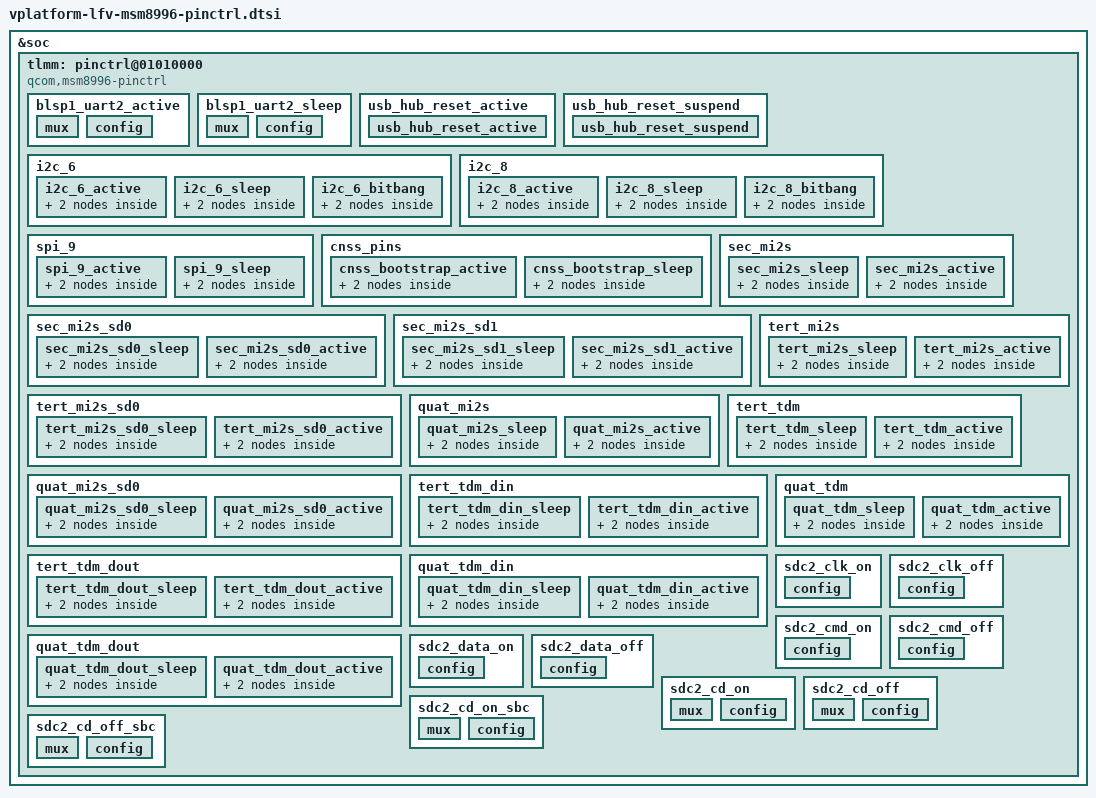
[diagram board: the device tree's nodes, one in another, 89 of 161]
/* Copyright (c) 2014-2018, The Linux Foundation. All rights reserved.
 *
 * This program is free software; you can redistribute it and/or modify
 * it under the terms of the GNU General Public License version 2 and
 * only version 2 as published by the Free Software Foundation.
 *
 * This program is distributed in the hope that it will be useful,
 * but WITHOUT ANY WARRANTY; without even the implied warranty of
 * MERCHANTABILITY or FITNESS FOR A PARTICULAR PURPOSE.  See the
 * GNU General Public License for more details.
 */

&soc {
	tlmm: pinctrl@01010000 {
		compatible = "qcom,msm8996-pinctrl";
		reg = <0x01010000 0x300000>;
		interrupts = <0 208 0>;
		gpio-controller;
		#gpio-cells = <2>;
		interrupt-controller;
		#interrupt-cells = <2>;

		blsp1_uart2_active: blsp1_uart2_active {
			mux {
				pins = "gpio41", "gpio42", "gpio43", "gpio44";
				function = "blsp_uart2";
			};

			config {
				pins = "gpio41", "gpio42", "gpio43", "gpio44";
				drive-strength = <2>;
				bias-disable;
			};
		};

		blsp1_uart2_sleep: blsp1_uart2_sleep {
			mux {
				pins = "gpio41", "gpio42", "gpio43", "gpio44";
				function = "gpio";
			};

			config {
				pins = "gpio41", "gpio42", "gpio43", "gpio44";
				drive-strength = <2>;
				bias-disable;
			};
		};

		usb_hub_reset_active: usb_hub_reset_active {
			usb_hub_reset_active {
				pins = "gpio103";
				drive-strength = <8>; /* 8 mA */
				bias-pull-up;  /* pull up */
				output-high;
			};
		};

		usb_hub_reset_suspend: usb_hub_reset_suspend {
			usb_hub_reset_suspend {
				pins = "gpio103";
				drive-strength = <2>; /* 2 mA */
				bias-disable= <0>; /* no pull */
			};
		};

		i2c_6 {
			i2c_6_active: i2c_6_active {
				mux {
					pins = "gpio27", "gpio28";
					function = "blsp_i2c6";
				};

				config {
					pins = "gpio27", "gpio28";
					drive-strength = <2>;
					bias-disable;
				};
			};

			i2c_6_sleep: i2c_6_sleep {
				mux {
					pins = "gpio27", "gpio28";
					function = "blsp_i2c6";
				};

				config {
					pins = "gpio27", "gpio28";
					drive-strength = <2>;
					bias-pull-up;
				};
			};

			i2c_6_bitbang: i2c_6_bitbang {
				mux {
					pins = "gpio27", "gpio28";
					function = "gpio";
				};

				config {
					pins = "gpio27", "gpio28";
					drive-strength = <2>;
					bias-pull-up;
				};
			};
		};

		i2c_8 {
			i2c_8_active: i2c_8_active {
				mux {
					pins = "gpio6", "gpio7";
					function = "blsp_i2c8";
				};

				config {
					pins = "gpio6", "gpio7";
					drive-strength = <4>;
					bias-disable;
				};
			};

			i2c_8_sleep: i2c_8_sleep {
				mux {
					pins = "gpio6", "gpio7";
					function = "blsp_i2c8";
				};

				config {
					pins = "gpio6", "gpio7";
					drive-strength = <4>;
					bias-pull-up;
				};
			};

			i2c_8_bitbang: i2c_8_bitbang {
				mux {
					pins = "gpio6", "gpio7";
					function = "gpio";
				};

				config {
					pins = "gpio6", "gpio7";
					drive-strength = <4>;
					bias-pull-up;
				};
			};
		};

		spi_9 {
			spi_9_active: spi_9_active {
				mux {
					pins = "gpio49", "gpio50", "gpio51",
								"gpio52";
					function = "blsp_spi9";
				};

				config {
					pins = "gpio49", "gpio50", "gpio51",
								"gpio52";
					drive-strength = <6>;
					bias-disable;
				};
			};

			spi_9_sleep: spi_9_sleep {
				mux {
					pins = "gpio49", "gpio50", "gpio51",
								"gpio52";
					function = "blsp_spi9";
				};

				config {
					pins = "gpio49", "gpio50", "gpio51",
								"gpio52";
					drive-strength = <6>;
					bias-disable;
				};
			};
		};

		cnss_pins {
			cnss_bootstrap_active: cnss_bootstrap_active {
				mux {
					pins = "gpio46";
					function = "gpio";
				};

				config {
					pins = "gpio46";
					drive-strength = <16>;
					output-high;
					bias-pull-up;
				};
			};
			cnss_bootstrap_sleep: cnss_bootstrap_sleep {
				mux {
					pins = "gpio46";
					function = "gpio";
				};

				config {
					pins = "gpio46";
					drive-strength = <2>;
					output-low;
					bias-pull-down;
				};
			};
		};

		sec_mi2s {
			sec_mi2s_sleep: sec_mi2s_sleep {
				mux {
					pins = "gpio80", "gpio81";
					function = "sec_mi2s";
				};

				config {
					pins = "gpio80", "gpio81";
					drive-strength = <2>;   /* 2 mA */
					bias-disable;         /* NO PULL */
				};
			};
			sec_mi2s_active: sec_mi2s_active {
				mux {
					pins = "gpio80", "gpio81";
					function = "sec_mi2s";
				};

				config {
					pins = "gpio80", "gpio81";
					drive-strength = <8>;   /* 8 mA */
					bias-disable;           /* NO PULL */
				};
			};
		};

		sec_mi2s_sd0 {
			sec_mi2s_sd0_sleep: sec_mi2s_sd0_sleep {
				mux {
					pins = "gpio82";
					function = "sec_mi2s";
				};

				config {
					pins = "gpio82";
					drive-strength = <2>;   /* 2 mA */
					bias-pull-down;         /* PULL DOWN */
				};
			};
			sec_mi2s_sd0_active: sec_mi2s_sd0_active {
				mux {
					pins = "gpio82";
					function = "sec_mi2s";
				};

				config {
					pins = "gpio82";
					drive-strength = <8>;   /* 8 mA */
					bias-disable;           /* NO PULL */
				};
			};
		};

		sec_mi2s_sd1 {
			sec_mi2s_sd1_sleep: sec_mi2s_sd1_sleep {
				mux {
					pins = "gpio83";
					function = "sec_mi2s";
				};

				config {
					pins = "gpio83";
					drive-strength = <2>;   /* 2 mA */
					bias-pull-down;         /* PULL DOWN */
				};
			};
			sec_mi2s_sd1_active: sec_mi2s_sd1_active {
				mux {
					pins = "gpio83";
					function = "sec_mi2s";
				};

				config {
					pins = "gpio83";
					drive-strength = <8>;   /* 8 mA */
					bias-disable;           /* NO PULL */
				};
			};
		};

		tert_mi2s {
			tert_mi2s_sleep: tert_mi2s_sleep {
				mux {
					pins = "gpio75", "gpio76";
					function = "ter_mi2s";
				};

				config {
					pins = "gpio75", "gpio76";
					drive-strength = <2>;   /* 2 mA */
					bias-pull-down;         /* PULL DOWN */
				};
			};
			tert_mi2s_active: tert_mi2s_active {
				mux {
					pins = "gpio75", "gpio76";
					function = "ter_mi2s";
				};

				config {
					pins = "gpio75", "gpio76";
					drive-strength = <8>;   /* 8 mA */
					bias-disable;           /* NO PULL */
					output-high;
				};
			};
		};

		tert_mi2s_sd0 {
			tert_mi2s_sd0_sleep: tert_mi2s_sd0_sleep {
				mux {
					pins = "gpio77";
					function = "ter_mi2s";
				};

				config {
					pins = "gpio77";
					drive-strength = <2>;   /* 2 mA */
					bias-pull-down;         /* PULL DOWN */
				};
			};
			tert_mi2s_sd0_active: tert_mi2s_sd0_active {
				mux {
					pins = "gpio77";
					function = "ter_mi2s";
				};

				config {
					pins = "gpio77";
					drive-strength = <8>;   /* 8 mA */
					bias-disable;           /* NO PULL */
				};
			};
		};

		quat_mi2s {
			quat_mi2s_sleep: quat_mi2s_sleep {
				mux {
					pins = "gpio58", "gpio59";
					function = "qua_mi2s";
				};

				config {
					pins = "gpio58", "gpio59";
					drive-strength = <2>;   /* 2 mA */
					bias-pull-down;         /* PULL DOWN */
				};
			};
			quat_mi2s_active: quat_mi2s_active {
				mux {
					pins = "gpio58", "gpio59";
					function = "qua_mi2s";
				};

				config {
					pins = "gpio58", "gpio59";
					drive-strength = <8>;   /* 8 mA */
					bias-disable;           /* NO PULL */
					output-high;
				};
			};
		};

		quat_mi2s_sd0 {
			quat_mi2s_sd0_sleep: quat_mi2s_sd0_sleep {
				mux {
					pins = "gpio60";
					function = "qua_mi2s";
				};

				config {
					pins = "gpio60";
					drive-strength = <2>;   /* 2 mA */
					bias-pull-down;         /* PULL DOWN */
				};
			};
			quat_mi2s_sd0_active: quat_mi2s_sd0_active {
				mux {
					pins = "gpio60";
					function = "qua_mi2s";
				};

				config {
					pins = "gpio60";
					drive-strength = <8>;   /* 8 mA */
					bias-disable;           /* NO PULL */
				};
			};
		};

		tert_tdm {
			tert_tdm_sleep: tert_tdm_sleep {
				mux {
					pins = "gpio75", "gpio76";
					function = "ter_mi2s";
				};

				config {
					pins = "gpio75", "gpio76";
					drive-strength = <2>;   /* 2 mA */
					bias-pull-down;         /* PULL DOWN */
				};
			};
			tert_tdm_active: tert_tdm_active {
				mux {
					pins = "gpio75", "gpio76";
					function = "ter_mi2s";
				};

				config {
					pins = "gpio75", "gpio76";
					drive-strength = <8>;   /* 8 mA */
					bias-disable;           /* NO PULL */
					output-high;
				};
			};
		};

		tert_tdm_din {
			tert_tdm_din_sleep: tert_tdm_din_sleep {
				mux {
					pins = "gpio77";
					function = "ter_mi2s";
				};

				config {
					pins = "gpio77";
					drive-strength = <2>;   /* 2 mA */
					bias-pull-down;         /* PULL DOWN */
				};
			};
			tert_tdm_din_active: tert_tdm_din_active {
				mux {
					pins = "gpio77";
					function = "ter_mi2s";
				};

				config {
					pins = "gpio77";
					drive-strength = <8>;   /* 8 mA */
					bias-disable;           /* NO PULL */
				};
			};
		};

		tert_tdm_dout {
			tert_tdm_dout_sleep: tert_tdm_dout_sleep {
				mux {
					pins = "gpio78";
					function = "ter_mi2s";
				};

				config {
					pins = "gpio78";
					drive-strength = <2>;   /* 2 mA */
					bias-pull-down;         /* PULL DOWN */
				};
			};
			tert_tdm_dout_active: tert_tdm_dout_active {
				mux {
					pins = "gpio78";
					function = "ter_mi2s";
				};

				config {
					pins = "gpio78";
					drive-strength = <8>;   /* 8 mA */
					bias-disable;           /* NO PULL */
				};
			};
		};

		quat_tdm {
			quat_tdm_sleep: quat_tdm_sleep {
				mux {
					pins = "gpio58", "gpio59";
					function = "qua_mi2s";
				};

				config {
					pins = "gpio58", "gpio59";
					drive-strength = <2>;   /* 2 mA */
					bias-pull-down;         /* PULL DOWN */
				};
			};
			quat_tdm_active: quat_tdm_active {
				mux {
					pins = "gpio58", "gpio59";
					function = "qua_mi2s";
				};

				config {
					pins = "gpio58", "gpio59";
					drive-strength = <8>;   /* 8 mA */
					bias-disable;           /* NO PULL */
					output-high;
				};
			};
		};

		quat_tdm_din {
			quat_tdm_din_sleep: quat_tdm_din_sleep {
				mux {
					pins = "gpio60";
					function = "qua_mi2s";
				};

				config {
					pins = "gpio60";
					drive-strength = <2>;   /* 2 mA */
					bias-pull-down;         /* PULL DOWN */
				};
			};
			quat_tdm_din_active: quat_tdm_din_active {
				mux {
					pins = "gpio60";
					function = "qua_mi2s";
				};

				config {
					pins = "gpio60";
					drive-strength = <8>;   /* 8 mA */
					bias-disable;           /* NO PULL */
				};
			};
		};

		quat_tdm_dout {
			quat_tdm_dout_sleep: quat_tdm_dout_sleep {
				mux {
					pins = "gpio61";
					function = "qua_mi2s";
				};

				config {
					pins = "gpio61";
					drive-strength = <2>;   /* 2 mA */
					bias-pull-down;         /* PULL DOWN */
				};
			};
			quat_tdm_dout_active: quat_tdm_dout_active {
				mux {
					pins = "gpio61";
					function = "qua_mi2s";
				};

				config {
					pins = "gpio61";
					drive-strength = <8>;   /* 8 mA */
					bias-disable;           /* NO PULL */
				};
			};
		};

		sdc2_clk_on: sdc2_clk_on {
			config {
				pins = "sdc2_clk";
				bias-disable;		/* NO pull */
				drive-strength = <16>;	/* 16 MA */
			};
		};

		sdc2_clk_off: sdc2_clk_off {
			config {
				pins = "sdc2_clk";
				bias-disable;		/* NO pull */
				drive-strength = <2>;	/* 2 MA */
			};
		};

		sdc2_cmd_on: sdc2_cmd_on {
			config {
				pins = "sdc2_cmd";
				bias-pull-up;		/* pull up */
				drive-strength = <10>;	/* 10 MA */
			};
		};

		sdc2_cmd_off: sdc2_cmd_off {
			config {
				pins = "sdc2_cmd";
				bias-pull-up;		/* pull up */
				drive-strength = <2>;	/* 2 MA */
			};
		};

		sdc2_data_on: sdc2_data_on {
			config {
				pins = "sdc2_data";
				bias-pull-up;		/* pull up */
				drive-strength = <10>;	/* 10 MA */
			};
		};

		sdc2_data_off: sdc2_data_off {
			config {
				pins = "sdc2_data";
				bias-pull-up;		/* pull up */
				drive-strength = <2>;	/* 2 MA */
			};
		};

		sdc2_cd_on: sdc2_cd_on {
			mux {
				pins = "gpio95";
				function = "gpio";
			};

			config {
				pins = "gpio95";
				bias-pull-up;		/* pull up */
				drive-strength = <16>;	/* 16 MA */
			};
		};

		sdc2_cd_off: sdc2_cd_off {
			mux {
				pins = "gpio95";
				function = "gpio";
			};

			config {
				pins = "gpio95";
				bias-pull-up;		/* pull up */
				drive-strength = <2>;	/* 2 MA */
			};
		};

		sdc2_cd_on_sbc: sdc2_cd_on_sbc {
			mux {
				pins = "gpio38";
				function = "gpio";
			};

			config {
				pins = "gpio38";
				bias-pull-up;		/* pull up */
				drive-strength = <16>;	/* 16 MA */
			};
		};

		sdc2_cd_off_sbc: sdc2_cd_off_sbc {
			mux {
				pins = "gpio38";
				function = "gpio";
			};

			config {
				pins = "gpio38";
				bias-pull-up;		/* pull up */
				drive-strength = <2>;	/* 2 MA */
			};
		};
	};
};
